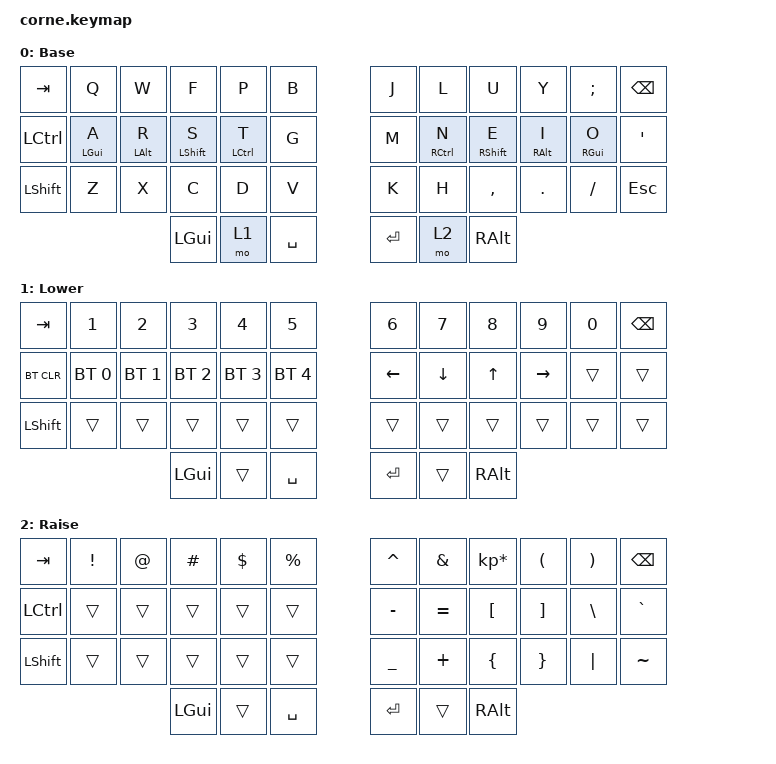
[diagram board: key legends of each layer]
/*
 * Copyright (c) 2020 The ZMK Contributors
 *
 * SPDX-License-Identifier: MIT
 */
#include <behaviors.dtsi>
#include <dt-bindings/zmk/keys.h>
#include <dt-bindings/zmk/bt.h>

/ {
        behaviors {
                hm: homerow_mods {
                        compatible = "zmk,behavior-hold-tap";
                        #binding-cells = <2>;
                        tapping-term-ms = <280>;
                        quick-tap-ms = <175>;
                        require-prior-idle-ms = <150>;
                        flavor = "balanced";
                        hold-trigger-key-positions = <6 7 8 9 10 11 18 19 20 21 22 23 30 31 32 33 34 35 39 40 41>;
                        hold-trigger-on-release;
                        bindings = <&kp>, <&kp>;
                };
                hm_r: homerow_mods_right {
                        compatible = "zmk,behavior-hold-tap";
                        #binding-cells = <2>;
                        tapping-term-ms = <280>;
                        quick-tap-ms = <175>;
                        require-prior-idle-ms = <150>;
                        flavor = "balanced";
                        hold-trigger-key-positions = <0 1 2 3 4 5 12 13 14 15 16 17 24 25 26 27 28 29 36 37 38>;
                        hold-trigger-on-release;
                        bindings = <&kp>, <&kp>;
                };
        };

        keymap {
                compatible = "zmk,keymap";
                default_layer {
                        display-name = "Base";
                        bindings = 
   &kp TAB       &kp Q        &kp W        &kp F         &kp P         &kp B         &kp J  &kp L         &kp U         &kp Y        &kp SEMI      &kp BSPC
   &kp LCTRL     &hm LGUI A   &hm LALT R   &hm LSHFT S   &hm LCTRL T   &kp G         &kp M  &hm_r RCTRL N &hm_r RSHFT E &hm_r RALT I &hm_r RGUI O  &kp SQT
   &kp LSHFT     &kp Z        &kp X        &kp C         &kp D         &kp V         &kp K  &kp H         &kp COMMA     &kp DOT      &kp FSLH      &kp ESC
                              &kp LGUI     &mo 1         &kp SPACE     &kp RET       &mo 2  &kp RALT
                        >;
                };
                lower_layer {
                        display-name = "Lower";
                        bindings = 
   &kp TAB    &kp N1       &kp N2       &kp N3       &kp N4       &kp N5       &kp N6   &kp N7   &kp N8 &kp N9    &kp N0 &kp BSPC
   &bt BT_CLR &bt BT_SEL 0 &bt BT_SEL 1 &bt BT_SEL 2 &bt BT_SEL 3 &bt BT_SEL 4 &kp LEFT &kp DOWN &kp UP &kp RIGHT &trans &trans
   &kp LSHFT  &trans       &trans       &trans       &trans       &trans       &trans   &trans   &trans &trans    &trans &trans
                            &kp LGUI     &trans       &kp SPACE    &kp RET      &trans   &kp RALT
                        >;
                };
                raise_layer {
                        display-name = "Raise";
                        bindings = 
   &kp TAB   &kp EXCL &kp AT &kp HASH &kp DLLR &kp PRCNT  &kp CARET &kp AMPS  &kp KP_MULTIPLY &kp LPAR &kp RPAR &kp BSPC
   &kp LCTRL &trans   &trans &trans   &trans   &trans     &kp MINUS &kp EQUAL &kp LBKT        &kp RBKT &kp BSLH &kp GRAVE
   &kp LSHFT &trans   &trans &trans   &trans   &trans     &kp UNDER &kp PLUS  &kp LBRC        &kp RBRC &kp PIPE &kp TILDE
                       &kp LGUI &trans &kp SPACE          &kp RET   &trans    &kp RALT
                        >;
                };
                extra_1 {
                        status = "reserved";
                };
                extra_2 {
                        status = "reserved";
                };
                extra_3 {
                        status = "reserved";
                };
        };
};
